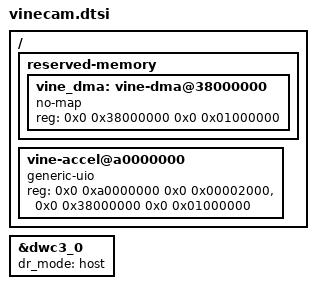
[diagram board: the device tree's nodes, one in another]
/*
 *  vinecam.dtsi - what Linux must be told so a process can drive the accelerator
 *
 *  build.sh appends this to the PetaLinux project's system-user.dtsi. Three
 *  things, each the minimum that works:
 *
 *  1. A carve-out of DDR the kernel never touches: 16 MB at 0x3800_0000.
 *
 *     The accelerator reads its weights, parameters and image from DDR over
 *     S_AXI_HP0_FPD, which neither translates virtual addresses nor snoops the
 *     APU's caches. So those buffers must be physically contiguous, at an
 *     address known in advance, and never cached. `no-map` gives all three: the
 *     kernel leaves the range out of its own memory map entirely - so no cache
 *     line of it can exist - and the application maps it uncached through UIO
 *     (firmware/linux/include/dmaregion.h has the argument in full).
 *
 *     Where: S_AXI_HP0_FPD reaches DDR_LOW only, 0 to 2 GB
 *     (build/bd_<cfg>/address_map.rpt), and the base registers are 32 bits, so
 *     below 2 GB is a hard limit. 0x3800_0000 also stays clear of where
 *     PetaLinux's U-Boot loads the kernel (0x0020_0000), the device tree, the
 *     ramdisk (0x0400_0000) and image.ub (0x1000_0000). vine_uio.c checks
 *     /proc/iomem at start-up and refuses the region if the kernel lists any of
 *     it as System RAM - which is what a missing `no-map` looks like.
 *
 *     Size: the blobs are 2,368,256 bytes and the image 150,528; 16 MB is
 *     generous, and 2 GB is not short of it.
 *
 *  2. The accelerator, as ONE UIO device with two maps:
 *
 *         map0   the AXI-Lite CSR, 8 KB at 0xA000_0000 (scripts/make_bd.tcl)
 *         map1   the carve-out above
 *
 *     compatible = "generic-uio" is matched by uio_pdrv_genirq when the kernel
 *     command line has uio_pdrv_genirq.of_id=generic-uio, which build.sh adds.
 *     If it is missing, vinecam binds the driver itself through driver_override
 *     and says so. The UIO device's name is the node's name, "vine-accel",
 *     which is how vinecam finds it - the uioN number is not stable.
 *
 *     No `interrupts`: vinecam polls, as the baremetal driver does (the run is
 *     ~6 ms, shorter than a scheduler tick). The line exists - pl_ps_irq0[0],
 *     GIC SPI 89 - for a later version that wants to block in read() instead.
 *
 *     PetaLinux's own device-tree generator may ALSO emit a node for u_accel
 *     (a module reference typed PERIPHERAL in the .hwh). That is harmless: no
 *     driver matches it, and a DT node claims no resources by itself.
 *
 *  3. USB in host mode, for the webcam. The ZCU104's USB 3.0 port is the PS's
 *     USB0 (enabled by the board preset); host is what it must be for a camera
 *     to enumerate, whatever the generated tree says.
 *
 *  Deliberately NOT here: the kernel command line. A chosen/bootargs in this
 *  file would REPLACE PetaLinux's, including whatever it needs to find its root
 *  filesystem, so build.sh appends to PetaLinux's generated line instead.
 */

/ {
	reserved-memory {
		#address-cells = <2>;
		#size-cells = <2>;
		ranges;

		vine_dma: vine-dma@38000000 {
			no-map;
			reg = <0x0 0x38000000 0x0 0x01000000>;
		};
	};

	vine-accel@a0000000 {
		compatible = "generic-uio";
		reg = <0x0 0xa0000000 0x0 0x00002000>,   /* map0: the CSR         */
		      <0x0 0x38000000 0x0 0x01000000>;   /* map1: the DMA region  */
	};
};

&dwc3_0 {
	dr_mode = "host";
};
